VERSION "HNNBNNNYNNNNNNNNNNNNNNNNNNNNNNNNNNNNNNNNNN/4/%%%/4/'%**4NNN///"

NS_ :

BS_:

BU_: Allrad_Haldex AreaView_MQB BAP_Tester Bremse_ABS_MK100 Bremse_ESP_EPB_EBC460Vi Bremse_ESP_EPB_MK100 Bremse_ESP_MK100 Daempfer Gateway_MQB Lenkhilfe_EPS PDC PDC_PLA

BO_ 3221225472 VECTOR__INDEPENDENT_SIG_MSG: 0 Vector__XXX
 SG_ ESP_QBit_Gierrate : 0|1@1+ (1,0) [0|1] "" Vector__XXX

BO_ 987 BCM_Turn_Signal: 8 Vector__XXX
 SG_ BCM_Right_turn : 51|1@1+ (1,0) [0|1] "" Vector__XXX
 SG_ BCM_Left_turn : 50|1@1+ (1,0) [0|1] "" Vector__XXX

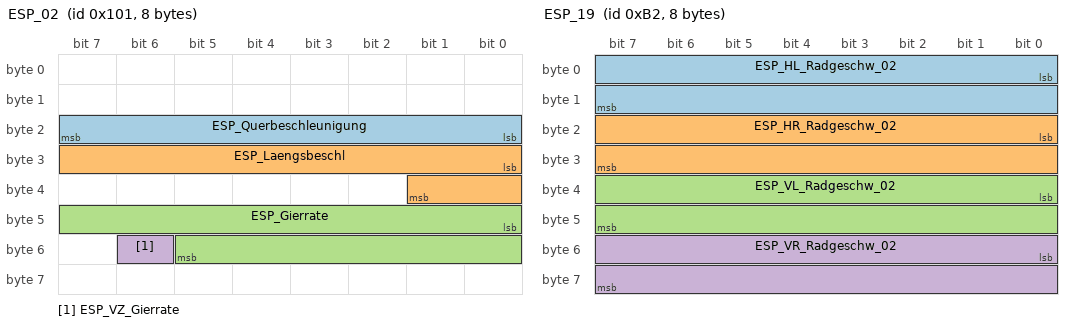
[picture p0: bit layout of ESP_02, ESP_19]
BO_ 257 ESP_02: 8 Bremse_ABS_MK100
 SG_ ESP_Querbeschleunigung : 16|8@1+ (0.01,-1.27) [-1.27|1.27] "Unit_ForceOfGravi"  Allrad_Haldex,AreaView_MQB,Daempfer,Gateway_MQB,Lenkhilfe_EPS
 SG_ ESP_Laengsbeschl : 24|10@1+ (0.03125,-16) [-16|15.90625] "Unit_MeterPerSeconSquar"  Allrad_Haldex,AreaView_MQB,Daempfer,Gateway_MQB,Lenkhilfe_EPS,PDC_PLA
 SG_ ESP_Gierrate : 40|14@1+ (0.01,0) [0|163.82] "Unit_DegreOfArcPerSecon"  Allrad_Haldex,AreaView_MQB,Daempfer,Gateway_MQB,Lenkhilfe_EPS,PDC_PLA
 SG_ ESP_VZ_Gierrate : 54|1@1+ (1,0) [0|1] ""  Allrad_Haldex,AreaView_MQB,Daempfer,Gateway_MQB,Lenkhilfe_EPS,PDC_PLA

BO_ 178 ESP_19: 8 Bremse_ABS_MK100
 SG_ ESP_HL_Radgeschw_02 : 0|16@1+ (0.0075,0) [0|491.49] "Unit_KiloMeterPerHour"  Allrad_Haldex,AreaView_MQB,Gateway_MQB,Lenkhilfe_EPS,PDC_PLA
 SG_ ESP_HR_Radgeschw_02 : 16|16@1+ (0.0075,0) [0|491.49] "Unit_KiloMeterPerHour"  Allrad_Haldex,AreaView_MQB,Gateway_MQB,Lenkhilfe_EPS,PDC_PLA
 SG_ ESP_VL_Radgeschw_02 : 32|16@1+ (0.0075,0) [0|491.49] "Unit_KiloMeterPerHour"  Allrad_Haldex,AreaView_MQB,Gateway_MQB,Lenkhilfe_EPS,PDC_PLA
 SG_ ESP_VR_Radgeschw_02 : 48|16@1+ (0.0075,0) [0|491.49] "Unit_KiloMeterPerHour"  Allrad_Haldex,AreaView_MQB,Gateway_MQB,Lenkhilfe_EPS,PDC_PLA

BO_ 253 ESP_21: 8 Bremse_ABS_MK100
 SG_ ESP_v_Signal : 32|16@1+ (0.01,0) [0|655.32] "Unit_KiloMeterPerHour"  AreaView_MQB,Daempfer,Gateway_MQB,Lenkhilfe_EPS,PDC,PDC_PLA

BO_ 134 LWI_01: 8 Lenkhilfe_EPS
 SG_ LWI_Lenkradwinkel : 16|13@1+ (0.1,0) [0|800] "Unit_DegreOfArc"  Allrad_Haldex,AreaView_MQB,Bremse_ABS_MK100,Bremse_ESP_EPB_EBC460Vi,Bremse_ESP_EPB_MK100,Bremse_ESP_MK100,Daempfer,Gateway_MQB,PDC,PDC_PLA
 SG_ LWI_VZ_Lenkradwinkel : 29|1@1+ (1,0) [0|1] ""  Allrad_Haldex,AreaView_MQB,Bremse_ABS_MK100,Bremse_ESP_EPB_EBC460Vi,Bremse_ESP_EPB_MK100,Bremse_ESP_MK100,Daempfer,Gateway_MQB,PDC,PDC_PLA

BO_TX_BU_ 257 : Bremse_ABS_MK100,Bremse_ESP_EPB_EBC460Vi,Bremse_ESP_EPB_MK100,Bremse_ESP_MK100;
BO_TX_BU_ 178 : Bremse_ABS_MK100,Bremse_ESP_EPB_EBC460Vi,Bremse_ESP_EPB_MK100,Bremse_ESP_MK100;
BO_TX_BU_ 253 : Bremse_ABS_MK100,Bremse_ESP_EPB_EBC460Vi,Bremse_ESP_EPB_MK100,Bremse_ESP_MK100;

CM_ "MQB_FCAN_V7.13F Generated by BUSNET NG Produktiv 9.2.3";
CM_ BU_ Allrad_Haldex "Längssperre/Allrad";
CM_ BU_ AreaView_MQB "Areaview MQB";
CM_ BU_ Bremse_ABS_MK100 "Bremse Continental MK100 (ABS)";
CM_ BU_ Bremse_ESP_EPB_EBC460Vi "Bremse TRW EBC460Vi (ESC mit integrierter EPB)";
CM_ BU_ Bremse_ESP_EPB_MK100 "Bremse Continental MK100 (ESC mit integrierter EPB)";
CM_ BU_ Bremse_ESP_MK100 "Bremse Continental MK100 (ESC) ";
CM_ BU_ Daempfer "Geregelter Dämpfer MQB A/B";
CM_ BU_ Gateway_MQB "Separates Gateway MQB A/B/E, MQB A0 Standard+/High";
CM_ BU_ Lenkhilfe_EPS "Elektromechanische Lenkhilfe MQB";
CM_ BU_ PDC "Einparkhilfe MQB/PQ26";
CM_ BU_ PDC_PLA "Einparkhilfe mit integriertem Park-Lenk-Assistenten MQB/PQ26";
CM_ BO_ 3221225472 "This is a message for not used signals, created by Vector CANdb++ DBC OLE DB Provider.";
CM_ SG_ 3221225472 ESP_QBit_Gierrate "QBit der Gierrate. Gesetzt bei Ersatzwert, Init oder Fehler. 
";
CM_ SG_ 257 ESP_Querbeschleunigung "Beschleunigungswert in y-Achse

MLB: Gemessener Wert
0xFF = Fehler (wie bereits im Wertebereich spezifizert)
Bei ESP-Abschaltung durch modellgestützte Überwachung wird das Signal weiterhin ausgegeben.
Im AU64x und AU57x erfolgt die Bereitstellung der";
CM_ SG_ 257 ESP_Laengsbeschl "Beschleunigungswert in x-Achse

MLB: Im AU64x und AU57x erfolgt die Bereitstellung der Sensorwerte durch SARA-SG! Im AU64x und AU57x wird bei ESP-Abschaltung durch modellgestützte Überwachung das Signal weiterhin ausgegeben.

MQB: Sensorrohwert Längsb";
CM_ SG_ 257 ESP_Gierrate "Winkelgeschwindigkeit um die z-Achse, ESP_VZ_Gierrate & ESP_QBit_Gierrate beachten !!!

MLB: gemessener Wert
tatsächliche Auflösung Bosch ESP: 0,27 Grad/s

Ab AU64x Auflösung wie die tatsächliche Skalierung 0,01. Im AU64x und AU57x wird bei ESP-Absch";
CM_ SG_ 257 ESP_VZ_Gierrate "Vorzeichen der Gierrate";
CM_ SG_ 178 ESP_HL_Radgeschw_02 "Radgeschwindigkeit hinten links";
CM_ SG_ 178 ESP_HR_Radgeschw_02 "Radgeschwindigkeit hinten rechts";
CM_ SG_ 178 ESP_VL_Radgeschw_02 "Radgeschwindigkeit vorne links";
CM_ SG_ 178 ESP_VR_Radgeschw_02 "Radgeschwindigkeit vorne rechts";
CM_ BO_ 253 "Neue Momente im MQB
Struktur ab MQB mit CRC8 entstanden aus ESP_01";
CM_ SG_ 253 ESP_v_Signal "Geschwindigkeitssignal vom ABS/ASR oder ESP. Mittelwert der angetriebenen Räder.
Bei MSR oder ABS Eingriffen wird die ABS-Referenzgeschwindigkeit für >= 200ms eingespiegelt (Zeit wird mit Aktiv-Flanke der Funktionsbits getriggert)

MQB: Bei Frontantrie";
CM_ BO_ 134 "ab MQB mit CRC in Byte 1";
CM_ SG_ 134 LWI_Lenkradwinkel "Wertebereich = +/- 800 Grad
Auflösung = 0,1 Grad
ACHTUNG: spezifizierte Interne Auflösung des Sensors beträgt aber nur Schrittweite 0,5 Grad!

Hinweis:
MLB: Zusätzlich gestellte Winkel bei Dynamiklenkung beachten !
MQB: Nicht konstante Lenkübersetzu";
CM_ SG_ 134 LWI_VZ_Lenkradwinkel "Vorzeichen Lenkradwinkel gemäss DIN70000; 
Nullstellung = +0";
BA_DEF_  "DBName" STRING ;
BA_DEF_  "GenNWMApBusSleep" STRING ;
BA_DEF_  "GenNWMApCanNormal" STRING ;
BA_DEF_  "GenNWMApCanOff" STRING ;
BA_DEF_  "GenNWMApCanOn" STRING ;
BA_DEF_  "GenNWMApCanSleep" STRING ;
BA_DEF_  "GenNWMApCanWakeUp" STRING ;
BA_DEF_  "GenNWMGotoMode_Awake" STRING ;
BA_DEF_  "GenNWMGotoMode_BusSleep" STRING ;
BA_DEF_  "GenNWMSleepTime" INT 0 1000000;
BA_DEF_  "GenNWMTalkNM" STRING ;
BA_DEF_  "Manufacturer" STRING ;
BA_DEF_  "NmhBaseAddress" HEX 0 536870911;
BA_DEF_  "NmhMessageCount" INT 0 256;
BA_DEF_  "NmType" STRING ;
BA_DEF_  "VAGTP20_SetupMessageCount" INT 0 255;
BA_DEF_  "VAGTP20_SetupStartAddress" HEX 0 2047;
BA_DEF_  "VersionDay" INT 1 31;
BA_DEF_  "VersionMonth" INT 1 12;
BA_DEF_  "VersionWeek" INT 1 52;
BA_DEF_  "VersionYear" INT 0 99;
BA_DEF_  "VersionNumber" INT 0 65535;
BA_DEF_  "Baudrate" INT 0 1000000;
BA_DEF_  "SamplePointMin" INT 1 100;
BA_DEF_  "SamplePointMax" INT 1 100;
BA_DEF_  "SyncJumpWidthMin" INT 1 4;
BA_DEF_  "SyncJumpWidthMax" INT 1 4;
BA_DEF_  "NmhTimeoutTimer" INT 0 65535;
BA_DEF_  "NmhWaitBusSleepTimer" INT 0 65535;
BA_DEF_  "NmhPrepareBusSleepTimer" INT 0 65535;
BA_DEF_  "NmhLongTimer" INT 0 65535;
BA_DEF_  "NmhNStart" INT 0 255;
BA_DEF_ BU_  "GenNodAutoGenDsp" ENUM  "No","Yes";
BA_DEF_ BU_  "GenNodAutoGenSnd" ENUM  "No","Yes";
BA_DEF_ BU_  "GenNodSleepTime" INT 0 1000000;
BA_DEF_ BU_  "ILUsed" ENUM  "No","Yes";
BA_DEF_ BU_  "ECUVariantDefault" ENUM  "No","Yes";
BA_DEF_ BU_  "ECUVariantGroup" STRING ;
BA_DEF_ BU_  "NodeLayerModules" STRING ;
BA_DEF_ BU_  "NmhNode" ENUM  "No","Yes";
BA_DEF_ BU_  "NmNode" ENUM  "No","Yes";
BA_DEF_ BO_  "DiagRequest" ENUM  "No","Yes";
BA_DEF_ BO_  "DiagResponse" ENUM  "No","Yes";
BA_DEF_ BO_  "DiagState" ENUM  "No","Yes";
BA_DEF_ BO_  "GenMsgChkConstant" HEX 0 4095;
BA_DEF_ BO_  "GenMsgCycleTime" INT 0 65535;
BA_DEF_ BO_  "GenMsgILSupport" ENUM  "No","Yes";
BA_DEF_ BO_  "GenMsgPDUConstants" STRING ;
BA_DEF_ BO_  "GenMsgSendType" ENUM  "Cyclic","not_used","not_used","not_used","not_used","not_used","not_used","IfActive","NoMsgSendType";
BA_DEF_ BO_  "GenMsgStartDelayTime" INT 0 100000;
BA_DEF_ BO_  "NmMessage" ENUM  "No","Yes";
BA_DEF_ BO_  "NmhMessage" ENUM  "No","Yes";
BA_DEF_ BO_  "MsgType" ENUM  "Application","NM ","NMH","TP2.0","ISO-TP ","BAP","EID","KS";
BA_DEF_ BO_  "VAGTP20_API" HEX 0 255;
BA_DEF_ BO_  "VAGTP20_DynConnection" ENUM  "No","Yes";
BA_DEF_ BO_  "VAGTP20_DynSetup" ENUM  "No","Yes";
BA_DEF_ BO_  "VAGTP20_StatConnection" ENUM  "No","Yes";
BA_DEF_ SG_  "GenSigActiveRepetitions" INT -2147483648 2147483647;
BA_DEF_ SG_  "GenSigSendType" ENUM  "Cyclic","OnWrite","OnWriteWithRepetition","OnChange","OnChangeWithRepetition","IfActive","IfActiveWithRepetition","NoSigSendType","OnChangeAndIfActive","OnChangeAndIfActiveWithRepetition";
BA_DEF_ SG_  "GenSigStartValue" INT -2147483648 2147483647;
BA_DEF_ SG_  "NWM-WakeupAllowed" ENUM  "No","Yes";
BA_DEF_ SG_  "GenSigFuncType" ENUM  "NoFunction","MsgCounter","CRC-8","XOR","XOR-2","DatedBit","SW-Kl15","CHK","Constant","Protocol","CRC-8-SAE_J1850";
BA_DEF_ SG_  "GenSigSwitchedByIgnition" ENUM  "No","Yes";
BA_DEF_ SG_  "Fehlerwert" HEX 0 2147483647;
BA_DEF_ SG_  "GenSigMissingSourceValue" HEX 0 2147483647;
BA_DEF_REL_ BU_SG_REL_  "GenSigTimeoutTime" INT 0 65535;
BA_DEF_DEF_  "DBName" "";
BA_DEF_DEF_  "GenNWMApBusSleep" "";
BA_DEF_DEF_  "GenNWMApCanNormal" "";
BA_DEF_DEF_  "GenNWMApCanOff" "";
BA_DEF_DEF_  "GenNWMApCanOn" "";
BA_DEF_DEF_  "GenNWMApCanSleep" "";
BA_DEF_DEF_  "GenNWMApCanWakeUp" "";
BA_DEF_DEF_  "GenNWMGotoMode_Awake" "";
BA_DEF_DEF_  "GenNWMGotoMode_BusSleep" "";
BA_DEF_DEF_  "GenNWMSleepTime" 0;
BA_DEF_DEF_  "GenNWMTalkNM" "";
BA_DEF_DEF_  "Manufacturer" "";
BA_DEF_DEF_  "NmhBaseAddress" 0;
BA_DEF_DEF_  "NmhMessageCount" 1;
BA_DEF_DEF_  "NmType" "None";
BA_DEF_DEF_  "VAGTP20_SetupMessageCount" 0;
BA_DEF_DEF_  "VAGTP20_SetupStartAddress" 0;
BA_DEF_DEF_  "VersionDay" 5.71632292177752E-316;
BA_DEF_DEF_  "VersionMonth" 5.72987692107927E-316;
BA_DEF_DEF_  "VersionWeek" 5.72991091279571E-316;
BA_DEF_DEF_  "VersionYear" 5.72991170330074E-316;
BA_DEF_DEF_  "VersionNumber" 0;
BA_DEF_DEF_  "Baudrate" 0;
BA_DEF_DEF_  "SamplePointMin" 1;
BA_DEF_DEF_  "SamplePointMax" 1;
BA_DEF_DEF_  "SyncJumpWidthMin" 1;
BA_DEF_DEF_  "SyncJumpWidthMax" 1;
BA_DEF_DEF_  "NmhTimeoutTimer" 0;
BA_DEF_DEF_  "NmhWaitBusSleepTimer" 0;
BA_DEF_DEF_  "NmhPrepareBusSleepTimer" 0;
BA_DEF_DEF_  "NmhLongTimer" 0;
BA_DEF_DEF_  "NmhNStart" 0;
BA_DEF_DEF_  "GenNodAutoGenDsp" "Yes";
BA_DEF_DEF_  "GenNodAutoGenSnd" "Yes";
BA_DEF_DEF_  "GenNodSleepTime" 0;
BA_DEF_DEF_  "ILUsed" "Yes";
BA_DEF_DEF_  "ECUVariantDefault" "Yes";
BA_DEF_DEF_  "ECUVariantGroup" "";
BA_DEF_DEF_  "NodeLayerModules" "";
BA_DEF_DEF_  "NmhNode" "Yes";
BA_DEF_DEF_  "NmNode" "No";
BA_DEF_DEF_  "DiagRequest" "No";
BA_DEF_DEF_  "DiagResponse" "No";
BA_DEF_DEF_  "DiagState" "No";
BA_DEF_DEF_  "GenMsgChkConstant" 0;
BA_DEF_DEF_  "GenMsgCycleTime" 0;
BA_DEF_DEF_  "GenMsgILSupport" "No";
BA_DEF_DEF_  "GenMsgPDUConstants" "";
BA_DEF_DEF_  "GenMsgSendType" "NoMsgSendType";
BA_DEF_DEF_  "GenMsgStartDelayTime" 0;
BA_DEF_DEF_  "NmMessage" "No";
BA_DEF_DEF_  "NmhMessage" "No";
BA_DEF_DEF_  "MsgType" "Application";
BA_DEF_DEF_  "VAGTP20_API" 0;
BA_DEF_DEF_  "VAGTP20_DynConnection" "No";
BA_DEF_DEF_  "VAGTP20_DynSetup" "No";
BA_DEF_DEF_  "VAGTP20_StatConnection" "No";
BA_DEF_DEF_  "GenSigActiveRepetitions" 0;
BA_DEF_DEF_  "GenSigSendType" "NoSigSendType";
BA_DEF_DEF_  "GenSigStartValue" 0;
BA_DEF_DEF_  "NWM-WakeupAllowed" "No";
BA_DEF_DEF_  "GenSigFuncType" "NoFunction";
BA_DEF_DEF_  "GenSigSwitchedByIgnition" "Yes";
BA_DEF_DEF_  "Fehlerwert" 0;
BA_DEF_DEF_  "GenSigMissingSourceValue" 0;
BA_DEF_DEF_REL_ "GenSigTimeoutTime" 0;
BA_ "GenNWMApBusSleep" "NMIndNetSDN()";
BA_ "GenNWMApCanNormal" "apCanNormal()";
BA_ "GenNWMApCanOff" "NMIndnetOff()";
BA_ "GenNWMApCanOn" "NMIndnetOn()";
BA_ "GenNWMApCanSleep" "apCanSleep()";
BA_ "GenNWMApCanWakeUp" "apCanWakeUp()";
BA_ "GenNWMGotoMode_Awake" "Nmh_ReqNetOn()";
BA_ "GenNWMGotoMode_BusSleep" "Nmh_ReqNetOff()";
BA_ "GenNWMSleepTime" 4000;
BA_ "GenNWMTalkNM" "Nmh_ReqNetOn()";
BA_ "Manufacturer" "VAG";
BA_ "NmhBaseAddress" 452984832;
BA_ "NmhMessageCount" 256;
BA_ "NmType" "NM-High";
BA_ "VAGTP20_SetupMessageCount" 128;
BA_ "VAGTP20_SetupStartAddress" 512;
BA_ "VersionDay" 12;
BA_ "VersionMonth" 6;
BA_ "VersionWeek" 24;
BA_ "VersionYear" 14;
BA_ "VersionNumber" 13;
BA_ "Baudrate" 500000;
BA_ "SamplePointMin" 80;
BA_ "SamplePointMax" 84;
BA_ "SyncJumpWidthMin" 2;
BA_ "SyncJumpWidthMax" 4;
BA_ "NmhTimeoutTimer" 1000;
BA_ "NmhWaitBusSleepTimer" 750;
BA_ "NmhPrepareBusSleepTimer" 500;
BA_ "NmhLongTimer" 200;
BA_ "NmhNStart" 20;
BA_ "DBName" "CAN";
BA_ "GenNodSleepTime" BU_ Allrad_Haldex 4000;
BA_ "ECUVariantGroup" BU_ Allrad_Haldex "Allrad";
BA_ "NmhNode" BU_ Allrad_Haldex 0;
BA_ "GenNodSleepTime" BU_ AreaView_MQB 4000;
BA_ "ECUVariantGroup" BU_ AreaView_MQB "Rearview";
BA_ "NodeLayerModules" BU_ AreaView_MQB "NMHigh.DLL";
BA_ "GenNodSleepTime" BU_ BAP_Tester 4000;
BA_ "ECUVariantGroup" BU_ BAP_Tester "BAP";
BA_ "NmhNode" BU_ BAP_Tester 0;
BA_ "GenNodSleepTime" BU_ Bremse_ABS_MK100 4000;
BA_ "ECUVariantDefault" BU_ Bremse_ABS_MK100 0;
BA_ "ECUVariantGroup" BU_ Bremse_ABS_MK100 "Bremse";
BA_ "NodeLayerModules" BU_ Bremse_ABS_MK100 "NMHigh.DLL";
BA_ "GenNodSleepTime" BU_ Bremse_ESP_EPB_EBC460Vi 4000;
BA_ "ECUVariantDefault" BU_ Bremse_ESP_EPB_EBC460Vi 0;
BA_ "ECUVariantGroup" BU_ Bremse_ESP_EPB_EBC460Vi "Bremse";
BA_ "NodeLayerModules" BU_ Bremse_ESP_EPB_EBC460Vi "NMHigh.DLL";
BA_ "GenNodSleepTime" BU_ Bremse_ESP_EPB_MK100 4000;
BA_ "ECUVariantGroup" BU_ Bremse_ESP_EPB_MK100 "Bremse";
BA_ "NodeLayerModules" BU_ Bremse_ESP_EPB_MK100 "NMHigh.DLL";
BA_ "GenNodSleepTime" BU_ Bremse_ESP_MK100 4000;
BA_ "ECUVariantDefault" BU_ Bremse_ESP_MK100 0;
BA_ "ECUVariantGroup" BU_ Bremse_ESP_MK100 "Bremse";
BA_ "NodeLayerModules" BU_ Bremse_ESP_MK100 "NMHigh.DLL";
BA_ "GenNodSleepTime" BU_ Daempfer 4000;
BA_ "ECUVariantGroup" BU_ Daempfer "Daempfer";
BA_ "NmhNode" BU_ Daempfer 0;
BA_ "GenNodSleepTime" BU_ Gateway_MQB 4000;
BA_ "ECUVariantGroup" BU_ Gateway_MQB "Gateway";
BA_ "NodeLayerModules" BU_ Gateway_MQB "NMHigh.DLL";
BA_ "GenNodSleepTime" BU_ Lenkhilfe_EPS 4000;
BA_ "ECUVariantGroup" BU_ Lenkhilfe_EPS "Lenkhilfe";
BA_ "NodeLayerModules" BU_ Lenkhilfe_EPS "NMHigh.DLL";
BA_ "GenNodSleepTime" BU_ PDC 4000;
BA_ "ECUVariantGroup" BU_ PDC "PDCPLA";
BA_ "NmhNode" BU_ PDC 0;
BA_ "GenNodSleepTime" BU_ PDC_PLA 4000;
BA_ "ECUVariantGroup" BU_ PDC_PLA "PDCPLA";
BA_ "NmhNode" BU_ PDC_PLA 0;
BA_ "GenMsgChkConstant" BO_ 257 170;
BA_ "GenMsgCycleTime" BO_ 257 20;
BA_ "GenMsgILSupport" BO_ 257 1;
BA_ "GenMsgPDUConstants" BO_ 257 "0xaa,0xaa,0xaa,0xaa,0xaa,0xaa,0xaa,0xaa,0xaa,0xaa,0xaa,0xaa,0xaa,0xaa,0xaa,0xaa";
BA_ "GenMsgSendType" BO_ 257 0;
BA_ "GenMsgCycleTime" BO_ 178 10;
BA_ "GenMsgILSupport" BO_ 178 1;
BA_ "GenMsgSendType" BO_ 178 0;
BA_ "GenMsgCycleTime" BO_ 253 20;
BA_ "GenMsgILSupport" BO_ 253 1;
BA_ "GenMsgPDUConstants" BO_ 253 "0xb4,0xef,0xf8,0x49,0x1e,0xe5,0xc2,0xc0,0x97,0x19,0x3c,0xc9,0xf1,0x98,0xd6,0x61";
BA_ "GenMsgSendType" BO_ 253 0;
BA_ "GenMsgChkConstant" BO_ 134 134;
BA_ "GenMsgCycleTime" BO_ 134 10;
BA_ "GenMsgILSupport" BO_ 134 1;
BA_ "GenMsgPDUConstants" BO_ 134 "0x86,0x86,0x86,0x86,0x86,0x86,0x86,0x86,0x86,0x86,0x86,0x86,0x86,0x86,0x86,0x86";
BA_ "GenMsgSendType" BO_ 134 0;
BA_ "GenSigSendType" SG_ 3221225472 ESP_QBit_Gierrate 0;
BA_ "GenSigStartValue" SG_ 3221225472 ESP_QBit_Gierrate 1;
BA_ "GenSigSwitchedByIgnition" SG_ 3221225472 ESP_QBit_Gierrate 0;
BA_ "GenSigSendType" SG_ 257 ESP_Querbeschleunigung 0;
BA_ "GenSigStartValue" SG_ 257 ESP_Querbeschleunigung 127;
BA_ "GenSigSwitchedByIgnition" SG_ 257 ESP_Querbeschleunigung 0;
BA_ "Fehlerwert" SG_ 257 ESP_Querbeschleunigung 255;
BA_ "GenSigSendType" SG_ 257 ESP_Laengsbeschl 0;
BA_ "GenSigStartValue" SG_ 257 ESP_Laengsbeschl 512;
BA_ "GenSigSwitchedByIgnition" SG_ 257 ESP_Laengsbeschl 0;
BA_ "Fehlerwert" SG_ 257 ESP_Laengsbeschl 1023;
BA_ "GenSigSendType" SG_ 257 ESP_Gierrate 0;
BA_ "GenSigSwitchedByIgnition" SG_ 257 ESP_Gierrate 0;
BA_ "Fehlerwert" SG_ 257 ESP_Gierrate 16383;
BA_ "GenSigSendType" SG_ 257 ESP_VZ_Gierrate 0;
BA_ "GenSigSwitchedByIgnition" SG_ 257 ESP_VZ_Gierrate 0;
BA_ "GenSigSendType" SG_ 178 ESP_HL_Radgeschw_02 0;
BA_ "GenSigStartValue" SG_ 178 ESP_HL_Radgeschw_02 65534;
BA_ "GenSigSwitchedByIgnition" SG_ 178 ESP_HL_Radgeschw_02 0;
BA_ "Fehlerwert" SG_ 178 ESP_HL_Radgeschw_02 65535;
BA_ "GenSigSendType" SG_ 178 ESP_HR_Radgeschw_02 0;
BA_ "GenSigStartValue" SG_ 178 ESP_HR_Radgeschw_02 65534;
BA_ "GenSigSwitchedByIgnition" SG_ 178 ESP_HR_Radgeschw_02 0;
BA_ "Fehlerwert" SG_ 178 ESP_HR_Radgeschw_02 65535;
BA_ "GenSigSendType" SG_ 178 ESP_VL_Radgeschw_02 0;
BA_ "GenSigStartValue" SG_ 178 ESP_VL_Radgeschw_02 65534;
BA_ "GenSigSwitchedByIgnition" SG_ 178 ESP_VL_Radgeschw_02 0;
BA_ "Fehlerwert" SG_ 178 ESP_VL_Radgeschw_02 65535;
BA_ "GenSigSendType" SG_ 178 ESP_VR_Radgeschw_02 0;
BA_ "GenSigStartValue" SG_ 178 ESP_VR_Radgeschw_02 65534;
BA_ "GenSigSwitchedByIgnition" SG_ 178 ESP_VR_Radgeschw_02 0;
BA_ "Fehlerwert" SG_ 178 ESP_VR_Radgeschw_02 65535;
BA_ "GenSigSendType" SG_ 253 ESP_v_Signal 0;
BA_ "GenSigStartValue" SG_ 253 ESP_v_Signal 65534;
BA_ "GenSigSwitchedByIgnition" SG_ 253 ESP_v_Signal 0;
BA_ "Fehlerwert" SG_ 253 ESP_v_Signal 65535;
BA_ "GenSigMissingSourceValue" SG_ 253 ESP_v_Signal 65534;
BA_ "GenSigSendType" SG_ 134 LWI_Lenkradwinkel 0;
BA_ "GenSigStartValue" SG_ 134 LWI_Lenkradwinkel 8190;
BA_ "Fehlerwert" SG_ 134 LWI_Lenkradwinkel 8191;
BA_ "GenSigSendType" SG_ 134 LWI_VZ_Lenkradwinkel 0;
BA_REL_ "GenSigTimeoutTime" BU_SG_REL_ Allrad_Haldex SG_ 257 ESP_Querbeschleunigung 500;
BA_REL_ "GenSigTimeoutTime" BU_SG_REL_ AreaView_MQB SG_ 257 ESP_Querbeschleunigung 500;
BA_REL_ "GenSigTimeoutTime" BU_SG_REL_ Daempfer SG_ 257 ESP_Querbeschleunigung 500;
BA_REL_ "GenSigTimeoutTime" BU_SG_REL_ Gateway_MQB SG_ 257 ESP_Querbeschleunigung 500;
BA_REL_ "GenSigTimeoutTime" BU_SG_REL_ Lenkhilfe_EPS SG_ 257 ESP_Querbeschleunigung 500;
BA_REL_ "GenSigTimeoutTime" BU_SG_REL_ Allrad_Haldex SG_ 257 ESP_Laengsbeschl 500;
BA_REL_ "GenSigTimeoutTime" BU_SG_REL_ AreaView_MQB SG_ 257 ESP_Laengsbeschl 500;
BA_REL_ "GenSigTimeoutTime" BU_SG_REL_ Daempfer SG_ 257 ESP_Laengsbeschl 500;
BA_REL_ "GenSigTimeoutTime" BU_SG_REL_ Lenkhilfe_EPS SG_ 257 ESP_Laengsbeschl 500;
BA_REL_ "GenSigTimeoutTime" BU_SG_REL_ PDC_PLA SG_ 257 ESP_Laengsbeschl 500;
BA_REL_ "GenSigTimeoutTime" BU_SG_REL_ Allrad_Haldex SG_ 257 ESP_Gierrate 500;
BA_REL_ "GenSigTimeoutTime" BU_SG_REL_ AreaView_MQB SG_ 257 ESP_Gierrate 500;
BA_REL_ "GenSigTimeoutTime" BU_SG_REL_ Daempfer SG_ 257 ESP_Gierrate 500;
BA_REL_ "GenSigTimeoutTime" BU_SG_REL_ Gateway_MQB SG_ 257 ESP_Gierrate 500;
BA_REL_ "GenSigTimeoutTime" BU_SG_REL_ Lenkhilfe_EPS SG_ 257 ESP_Gierrate 500;
BA_REL_ "GenSigTimeoutTime" BU_SG_REL_ PDC_PLA SG_ 257 ESP_Gierrate 500;
BA_REL_ "GenSigTimeoutTime" BU_SG_REL_ Allrad_Haldex SG_ 257 ESP_VZ_Gierrate 500;
BA_REL_ "GenSigTimeoutTime" BU_SG_REL_ AreaView_MQB SG_ 257 ESP_VZ_Gierrate 500;
BA_REL_ "GenSigTimeoutTime" BU_SG_REL_ Daempfer SG_ 257 ESP_VZ_Gierrate 500;
BA_REL_ "GenSigTimeoutTime" BU_SG_REL_ Gateway_MQB SG_ 257 ESP_VZ_Gierrate 500;
BA_REL_ "GenSigTimeoutTime" BU_SG_REL_ Lenkhilfe_EPS SG_ 257 ESP_VZ_Gierrate 500;
BA_REL_ "GenSigTimeoutTime" BU_SG_REL_ PDC_PLA SG_ 257 ESP_VZ_Gierrate 500;
BA_REL_ "GenSigTimeoutTime" BU_SG_REL_ Allrad_Haldex SG_ 178 ESP_HL_Radgeschw_02 500;
BA_REL_ "GenSigTimeoutTime" BU_SG_REL_ AreaView_MQB SG_ 178 ESP_HL_Radgeschw_02 500;
BA_REL_ "GenSigTimeoutTime" BU_SG_REL_ Lenkhilfe_EPS SG_ 178 ESP_HL_Radgeschw_02 500;
BA_REL_ "GenSigTimeoutTime" BU_SG_REL_ PDC_PLA SG_ 178 ESP_HL_Radgeschw_02 500;
BA_REL_ "GenSigTimeoutTime" BU_SG_REL_ Allrad_Haldex SG_ 178 ESP_HR_Radgeschw_02 500;
BA_REL_ "GenSigTimeoutTime" BU_SG_REL_ AreaView_MQB SG_ 178 ESP_HR_Radgeschw_02 500;
BA_REL_ "GenSigTimeoutTime" BU_SG_REL_ Lenkhilfe_EPS SG_ 178 ESP_HR_Radgeschw_02 500;
BA_REL_ "GenSigTimeoutTime" BU_SG_REL_ PDC_PLA SG_ 178 ESP_HR_Radgeschw_02 500;
BA_REL_ "GenSigTimeoutTime" BU_SG_REL_ Allrad_Haldex SG_ 178 ESP_VL_Radgeschw_02 500;
BA_REL_ "GenSigTimeoutTime" BU_SG_REL_ AreaView_MQB SG_ 178 ESP_VL_Radgeschw_02 500;
BA_REL_ "GenSigTimeoutTime" BU_SG_REL_ Lenkhilfe_EPS SG_ 178 ESP_VL_Radgeschw_02 500;
BA_REL_ "GenSigTimeoutTime" BU_SG_REL_ PDC_PLA SG_ 178 ESP_VL_Radgeschw_02 500;
BA_REL_ "GenSigTimeoutTime" BU_SG_REL_ Allrad_Haldex SG_ 178 ESP_VR_Radgeschw_02 500;
BA_REL_ "GenSigTimeoutTime" BU_SG_REL_ AreaView_MQB SG_ 178 ESP_VR_Radgeschw_02 500;
BA_REL_ "GenSigTimeoutTime" BU_SG_REL_ Lenkhilfe_EPS SG_ 178 ESP_VR_Radgeschw_02 500;
BA_REL_ "GenSigTimeoutTime" BU_SG_REL_ PDC_PLA SG_ 178 ESP_VR_Radgeschw_02 500;
BA_REL_ "GenSigTimeoutTime" BU_SG_REL_ AreaView_MQB SG_ 253 ESP_v_Signal 500;
BA_REL_ "GenSigTimeoutTime" BU_SG_REL_ Daempfer SG_ 253 ESP_v_Signal 500;
BA_REL_ "GenSigTimeoutTime" BU_SG_REL_ Gateway_MQB SG_ 253 ESP_v_Signal 500;
BA_REL_ "GenSigTimeoutTime" BU_SG_REL_ Lenkhilfe_EPS SG_ 253 ESP_v_Signal 500;
BA_REL_ "GenSigTimeoutTime" BU_SG_REL_ PDC SG_ 253 ESP_v_Signal 500;
BA_REL_ "GenSigTimeoutTime" BU_SG_REL_ PDC_PLA SG_ 253 ESP_v_Signal 500;
BA_REL_ "GenSigTimeoutTime" BU_SG_REL_ Allrad_Haldex SG_ 134 LWI_Lenkradwinkel 500;
BA_REL_ "GenSigTimeoutTime" BU_SG_REL_ AreaView_MQB SG_ 134 LWI_Lenkradwinkel 500;
BA_REL_ "GenSigTimeoutTime" BU_SG_REL_ Bremse_ABS_MK100 SG_ 134 LWI_Lenkradwinkel 500;
BA_REL_ "GenSigTimeoutTime" BU_SG_REL_ Bremse_ESP_EPB_EBC460Vi SG_ 134 LWI_Lenkradwinkel 500;
BA_REL_ "GenSigTimeoutTime" BU_SG_REL_ Bremse_ESP_EPB_MK100 SG_ 134 LWI_Lenkradwinkel 500;
BA_REL_ "GenSigTimeoutTime" BU_SG_REL_ Bremse_ESP_MK100 SG_ 134 LWI_Lenkradwinkel 500;
BA_REL_ "GenSigTimeoutTime" BU_SG_REL_ Daempfer SG_ 134 LWI_Lenkradwinkel 500;
BA_REL_ "GenSigTimeoutTime" BU_SG_REL_ PDC SG_ 134 LWI_Lenkradwinkel 500;
BA_REL_ "GenSigTimeoutTime" BU_SG_REL_ PDC_PLA SG_ 134 LWI_Lenkradwinkel 500;
BA_REL_ "GenSigTimeoutTime" BU_SG_REL_ Allrad_Haldex SG_ 134 LWI_VZ_Lenkradwinkel 500;
BA_REL_ "GenSigTimeoutTime" BU_SG_REL_ AreaView_MQB SG_ 134 LWI_VZ_Lenkradwinkel 500;
BA_REL_ "GenSigTimeoutTime" BU_SG_REL_ Bremse_ABS_MK100 SG_ 134 LWI_VZ_Lenkradwinkel 500;
BA_REL_ "GenSigTimeoutTime" BU_SG_REL_ Bremse_ESP_EPB_EBC460Vi SG_ 134 LWI_VZ_Lenkradwinkel 500;
BA_REL_ "GenSigTimeoutTime" BU_SG_REL_ Bremse_ESP_EPB_MK100 SG_ 134 LWI_VZ_Lenkradwinkel 500;
BA_REL_ "GenSigTimeoutTime" BU_SG_REL_ Bremse_ESP_MK100 SG_ 134 LWI_VZ_Lenkradwinkel 500;
BA_REL_ "GenSigTimeoutTime" BU_SG_REL_ Daempfer SG_ 134 LWI_VZ_Lenkradwinkel 500;
BA_REL_ "GenSigTimeoutTime" BU_SG_REL_ PDC SG_ 134 LWI_VZ_Lenkradwinkel 500;
BA_REL_ "GenSigTimeoutTime" BU_SG_REL_ PDC_PLA SG_ 134 LWI_VZ_Lenkradwinkel 500;
VAL_ 3221225472 ESP_QBit_Gierrate 0 "gueltiger_Wert" 1 "Ersatz_Init_oder_Fehlerwert" ;
VAL_ 257 ESP_Querbeschleunigung 255 "Fehler" ;
VAL_ 257 ESP_Laengsbeschl 1022 "Signal_nicht_vorhanden" 1023 "Fehler" ;
VAL_ 257 ESP_Gierrate 16383 "Fehler" ;
VAL_ 257 ESP_VZ_Gierrate 0 "positiv" 1 "negativ" ;
VAL_ 178 ESP_HL_Radgeschw_02 65533 "Unterspannung" 65534 "Init" 65535 "Fehler" ;
VAL_ 178 ESP_HR_Radgeschw_02 65533 "Unterspannung" 65534 "Init" 65535 "Fehler" ;
VAL_ 178 ESP_VL_Radgeschw_02 65533 "Unterspannung" 65534 "Init" 65535 "Fehler" ;
VAL_ 178 ESP_VR_Radgeschw_02 65533 "Unterspannung" 65534 "Init" 65535 "Fehler" ;
VAL_ 253 ESP_v_Signal 65533 "Unterspannung" 65534 "Init" 65535 "Fehler" ;
VAL_ 134 LWI_Lenkradwinkel 8190 "Init" 8191 "Fehler" ;
VAL_ 134 LWI_VZ_Lenkradwinkel 0 "positiv_links_von_der_Nullstellung" 1 "negativ" ;
